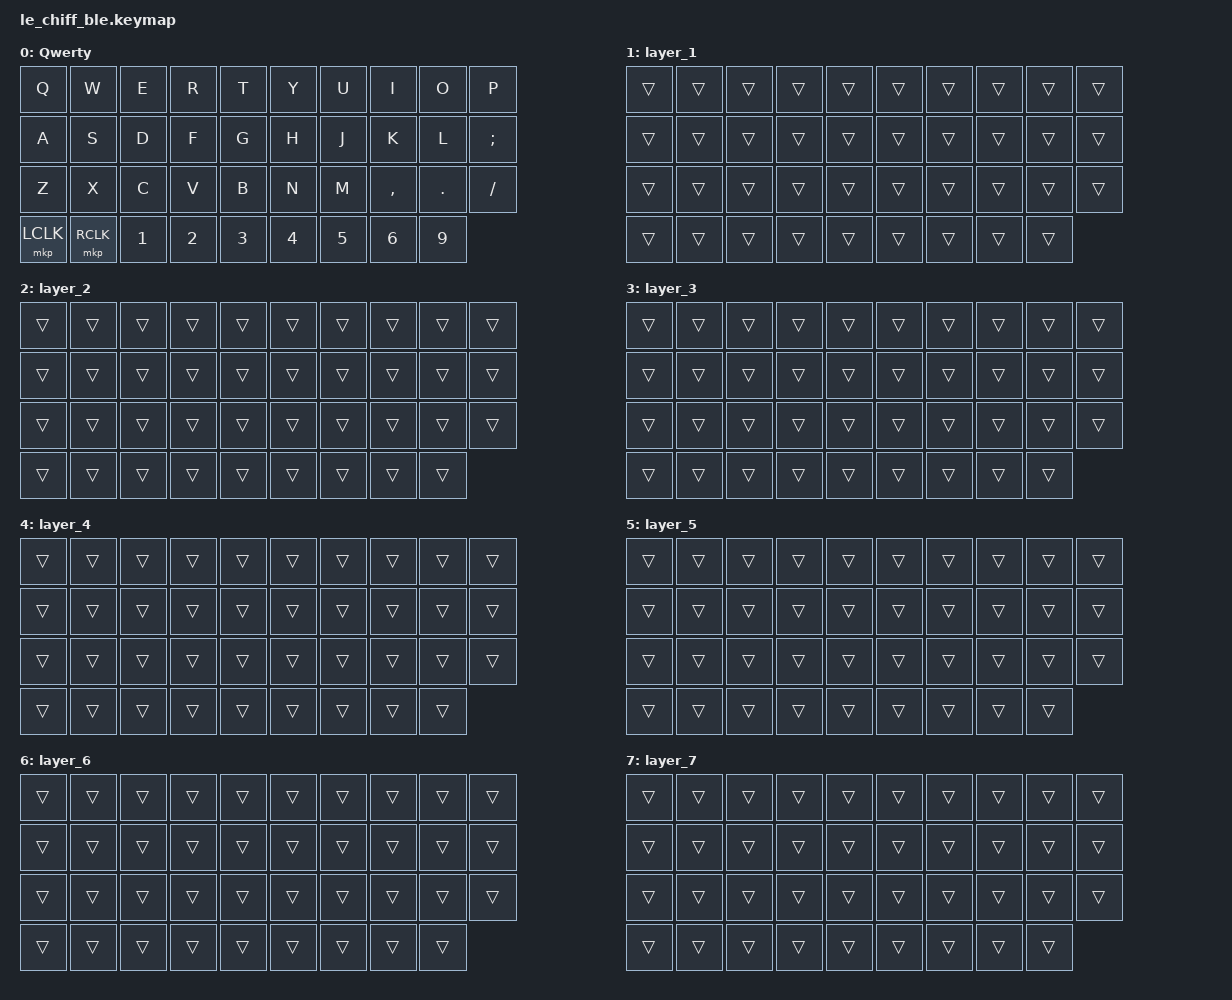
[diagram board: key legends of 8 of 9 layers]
/*
 * Copyright (c) 2021 @MangoIV
 *
 * SPDX-License-Identifier: MIT
 */

#define ZMK_MOUSE_DEFAULT_SCRL_VAL 35 // 10
#define ZMK_POINTING_DEFAULT_MOVE_VAL 2500  // 600
#define ZMK_POINTING_DEFAULT_SCRL_VAL 20    // 10

#define SPEED_POINTER 0
#define SPEED_SCROLL 1
#define SPEED_PREV 0
#define SPEED_NEXT 1
#define SPEED_RESET 2
#define SPEED_FINE_PREV 3
#define SPEED_FINE_NEXT 4
#define CIRQUE_MODE_RELATIVE 0
#define CIRQUE_MODE_ABSOLUTE 1
#define CIRQUE_MODE_TOGGLE 2

#include <behaviors/mouse_keys.dtsi>
#include <behaviors/runtime-sensor-rotate.dtsi>
#include <dt-bindings/zmk/mouse.h>
#include <input/processors.dtsi>
#include <zephyr/dt-bindings/input/input-event-codes.h>
#include <behaviors.dtsi>
#include <dt-bindings/zmk/keys.h>
#include <dt-bindings/zmk/pointing.h>

&msc {
    acceleration-exponent = <0>;      // 0
    time-to-max-speed-ms = <0>;       // 300
    delay-ms = <0>;                   // 0
};

&mmv {
    time-to-max-speed-ms = <400>;
    acceleration-exponent = <1>;
};

&glidepoint_listener {
    input-processors = <&pointer_processor 0 0 &drag_scroll_processor 1 8>;
};

/ {
    // === Cirque Pinnacle2 Trackpad Input Processors ===
    pointer_processor: pointer_processor {
        compatible = "zmk,input-processor-pointer-speed";
        #input-processor-cells = <2>;
        track-remainders;
        pointer-curve = "adaptive";
        pointer-curve-deadzone = <2>;
        pointer-curve-accel-multiplier = <1>;
        pointer-curve-accel-divisor = <12>;
        pointer-curve-max-delta = <120>;
        one-x-multiplier = <1>;
        one-x-divisor = <1>;
        min-percent = <10>;
        max-percent = <400>;
        initial-speed-position = <50>;
    };

    drag_scroll_processor: drag_scroll_processor {
        compatible = "zmk,input-processor-drag-scroll";
        #input-processor-cells = <2>;
        track-remainders;
        native-wheel-axis = "horizontal-when-enabled";
        scroll-min-step = <1>;
        one-x-multiplier = <1>;
        one-x-divisor = <1>;
        min-percent = <10>;
        max-percent = <1000>;
        initial-speed-position = <50>;
    };

    combos {
        compatible = "zmk,combos";

        combo_esc {
            timeout-ms = <50>;
            key-positions = <0 1>;
            bindings = <&kp ESC>;
        };

        left_bkt {
            bindings = <&kp LEFT_BRACKET>;
            key-positions = <2 3>;
            timeout-ms = <50>;
        };

        right_bkt {
            bindings = <&kp RIGHT_BRACKET>;
            key-positions = <7 6>;
            timeout-ms = <50>;
        };

        left_par {
            bindings = <&kp LEFT_PARENTHESIS>;
            key-positions = <12 13>;
            timeout-ms = <50>;
        };

        right_par {
            bindings = <&kp RIGHT_PARENTHESIS>;
            key-positions = <16 17>;
            timeout-ms = <50>;
        };

        left_brace {
            bindings = <&kp LEFT_BRACE>;
            key-positions = <22 23>;
            timeout-ms = <50>;
        };

        right_brace {
            bindings = <&kp RIGHT_BRACE>;
            key-positions = <26 27>;
            timeout-ms = <50>;
        };

        bac {
            bindings = <&kp BACKSLASH>;
            key-positions = <24 25>;
            timeout-ms = <50>;
        };

        pipe {
            bindings = <&kp PIPE>;
            key-positions = <14 15>;
            timeout-ms = <50>;
        };

        plus {
            bindings = <&kp PLUS>;
            key-positions = <11 12>;
        };

        equal {
            bindings = <&kp EQUAL>;
            key-positions = <18 17>;
        };
    };

    macros {
        dongle_bootload_macro: bootload_macro {
            compatible = "zmk,behavior-macro";
            #binding-cells = <0>;
            bindings = <&bootloader>;
            label = "BOOTLOAD_MACRO";
        };
    };

    behaviors {
        hm: homerow_mods {
            compatible = "zmk,behavior-hold-tap";
            label = "HOMEROW_MODS";
            bindings = <&kp>, <&kp>;

            #binding-cells = <2>;
            tapping-term-ms = <200>;
            quick-tap-ms = <180>;
            flavor = "tap-preferred";
        };

        ltq: ltq {
            compatible = "zmk,behavior-hold-tap";
            label = "LTQ";
            bindings = <&mo>, <&kp>;

            #binding-cells = <2>;
            tapping-term-ms = <200>;
            quick-tap-ms = <180>;
        };

        as: auto_shift {
            compatible = "zmk,behavior-hold-tap";
            label = "AUTO_SHIFT";
            bindings = <&kp>, <&kp>;

            #binding-cells = <2>;
            tapping-term-ms = <135>;
            quick-tap-ms = <0>;
        };

        rsr_vol: rsr_vol {
            compatible = "zmk,behavior-runtime-sensor-rotate";
            #sensor-binding-cells = <0>;
            tap-ms = <5>;
            cw-binding = <&kp C_VOL_UP>;
            ccw-binding = <&kp C_VOL_DN>;
        };

        rsr_trans: rsr_trans {
            compatible = "zmk,behavior-runtime-sensor-rotate";
            #sensor-binding-cells = <0>;
            tap-ms = <0>;
        };

        // === Cirque Pinnacle2 Trackpad Behaviors ===
        drgscrl: drag_scroll {
            compatible = "zmk,behavior-drag-scroll";
            #binding-cells = <0>;
        };

        ptr_spd: pointing_speed {
            compatible = "zmk,behavior-pointing-speed";
            #binding-cells = <2>;
        };

        crq_mode: crqm {
            compatible = "zmk,behavior-cirque-mode";
            #binding-cells = <1>;
        };

        sel_x: select_x {
            compatible = "zmk,behavior-hold-tap";
            #binding-cells = <2>;
            flavor = "tap-preferred";
            tapping-term-ms = <200>;
            quick-tap-ms = <150>;
            require-prior-idle-ms = <125>;
            bindings = <&mkp>, <&kp>;
        };

        ds_z: drag_scroll_z {
            compatible = "zmk,behavior-hold-tap";
            #binding-cells = <2>;
            flavor = "tap-preferred";
            tapping-term-ms = <200>;
            quick-tap-ms = <150>;
            require-prior-idle-ms = <125>;
            bindings = <&drgscrl>, <&kp>;
        };
    };

    keymap {
        compatible = "zmk,keymap";

        Qwery {
            label = "Qwerty";
            bindings = <
&kp Q      &kp W      &kp E   &kp R   &kp T   &kp Y   &kp U   &kp I      &kp O    &kp P
&kp A      &kp S      &kp D   &kp F   &kp G   &kp H   &kp J   &kp K      &kp L    &kp SEMI
&kp Z      &kp X      &kp C   &kp V   &kp B   &kp N   &kp M   &kp COMMA  &kp DOT  &kp FSLH
&mkp LCLK  &mkp RCLK  &kp N1  &kp N2  &kp N3  &kp N4  &kp N5  &kp N6     &kp N9
            >;

            sensor-bindings = <&rsr_vol &rsr_trans>;
        };

        layer_1 {
            sensor-bindings = <&rsr_vol &rsr_trans>;
            bindings = <
&trans  &trans  &trans  &trans  &trans  &trans  &trans  &trans  &trans  &trans
&trans  &trans  &trans  &trans  &trans  &trans  &trans  &trans  &trans  &trans
&trans  &trans  &trans  &trans  &trans  &trans  &trans  &trans  &trans  &trans
&trans  &trans  &trans  &trans  &trans  &trans  &trans  &trans  &trans
            >;
        };

        layer_2 {
            sensor-bindings = <&rsr_vol &rsr_trans>;
            bindings = <
&trans  &trans  &trans  &trans  &trans  &trans  &trans  &trans  &trans  &trans
&trans  &trans  &trans  &trans  &trans  &trans  &trans  &trans  &trans  &trans
&trans  &trans  &trans  &trans  &trans  &trans  &trans  &trans  &trans  &trans
&trans  &trans  &trans  &trans  &trans  &trans  &trans  &trans  &trans
            >;
        };

        layer_3 {
            sensor-bindings = <&rsr_vol &rsr_trans>;
            bindings = <
&trans  &trans  &trans  &trans  &trans  &trans  &trans  &trans  &trans  &trans
&trans  &trans  &trans  &trans  &trans  &trans  &trans  &trans  &trans  &trans
&trans  &trans  &trans  &trans  &trans  &trans  &trans  &trans  &trans  &trans
&trans  &trans  &trans  &trans  &trans  &trans  &trans  &trans  &trans
            >;
        };

        layer_4 {
            sensor-bindings = <&rsr_vol &rsr_trans>;
            bindings = <
&trans  &trans  &trans  &trans  &trans  &trans  &trans  &trans  &trans  &trans
&trans  &trans  &trans  &trans  &trans  &trans  &trans  &trans  &trans  &trans
&trans  &trans  &trans  &trans  &trans  &trans  &trans  &trans  &trans  &trans
&trans  &trans  &trans  &trans  &trans  &trans  &trans  &trans  &trans
            >;
        };

        layer_5 {
            sensor-bindings = <&rsr_vol &rsr_trans>;
            bindings = <
&trans  &trans  &trans  &trans  &trans  &trans  &trans  &trans  &trans  &trans
&trans  &trans  &trans  &trans  &trans  &trans  &trans  &trans  &trans  &trans
&trans  &trans  &trans  &trans  &trans  &trans  &trans  &trans  &trans  &trans
&trans  &trans  &trans  &trans  &trans  &trans  &trans  &trans  &trans
            >;
        };

        layer_6 {
            sensor-bindings = <&rsr_vol &rsr_trans>;
            bindings = <
&trans  &trans  &trans  &trans  &trans  &trans  &trans  &trans  &trans  &trans
&trans  &trans  &trans  &trans  &trans  &trans  &trans  &trans  &trans  &trans
&trans  &trans  &trans  &trans  &trans  &trans  &trans  &trans  &trans  &trans
&trans  &trans  &trans  &trans  &trans  &trans  &trans  &trans  &trans
            >;
        };

        layer_7 {
            sensor-bindings = <&rsr_vol &rsr_trans>;
            bindings = <
&trans  &trans  &trans  &trans  &trans  &trans  &trans  &trans  &trans  &trans
&trans  &trans  &trans  &trans  &trans  &trans  &trans  &trans  &trans  &trans
&trans  &trans  &trans  &trans  &trans  &trans  &trans  &trans  &trans  &trans
&trans  &trans  &trans  &trans  &trans  &trans  &trans  &trans  &trans
            >;
        };

        MOUSE {
            display-name = "MOUSE";
            sensor-bindings = <&rsr_vol &rsr_trans>;
            bindings = <
&mo 9  &trans  &trans  &trans  &trans  &trans  &trans  &trans  &trans  &trans
&trans  &trans  &trans  &trans  &trans  &mmv MOVE_LEFT  &mmv MOVE_DOWN  &mmv MOVE_UP  &mmv MOVE_RIGHT  &trans
&trans  &trans  &trans  &trans  &ptr_spd SPEED_POINTER SPEED_FINE_PREV  &trans  &ptr_spd SPEED_SCROLL SPEED_FINE_PREV  &trans  &trans
&trans  &trans  &trans  &trans  &trans  &ptr_spd SPEED_POINTER SPEED_RESET  &ptr_spd SPEED_SCROLL SPEED_RESET  &trans  &trans
            >;
        };
    };
};
